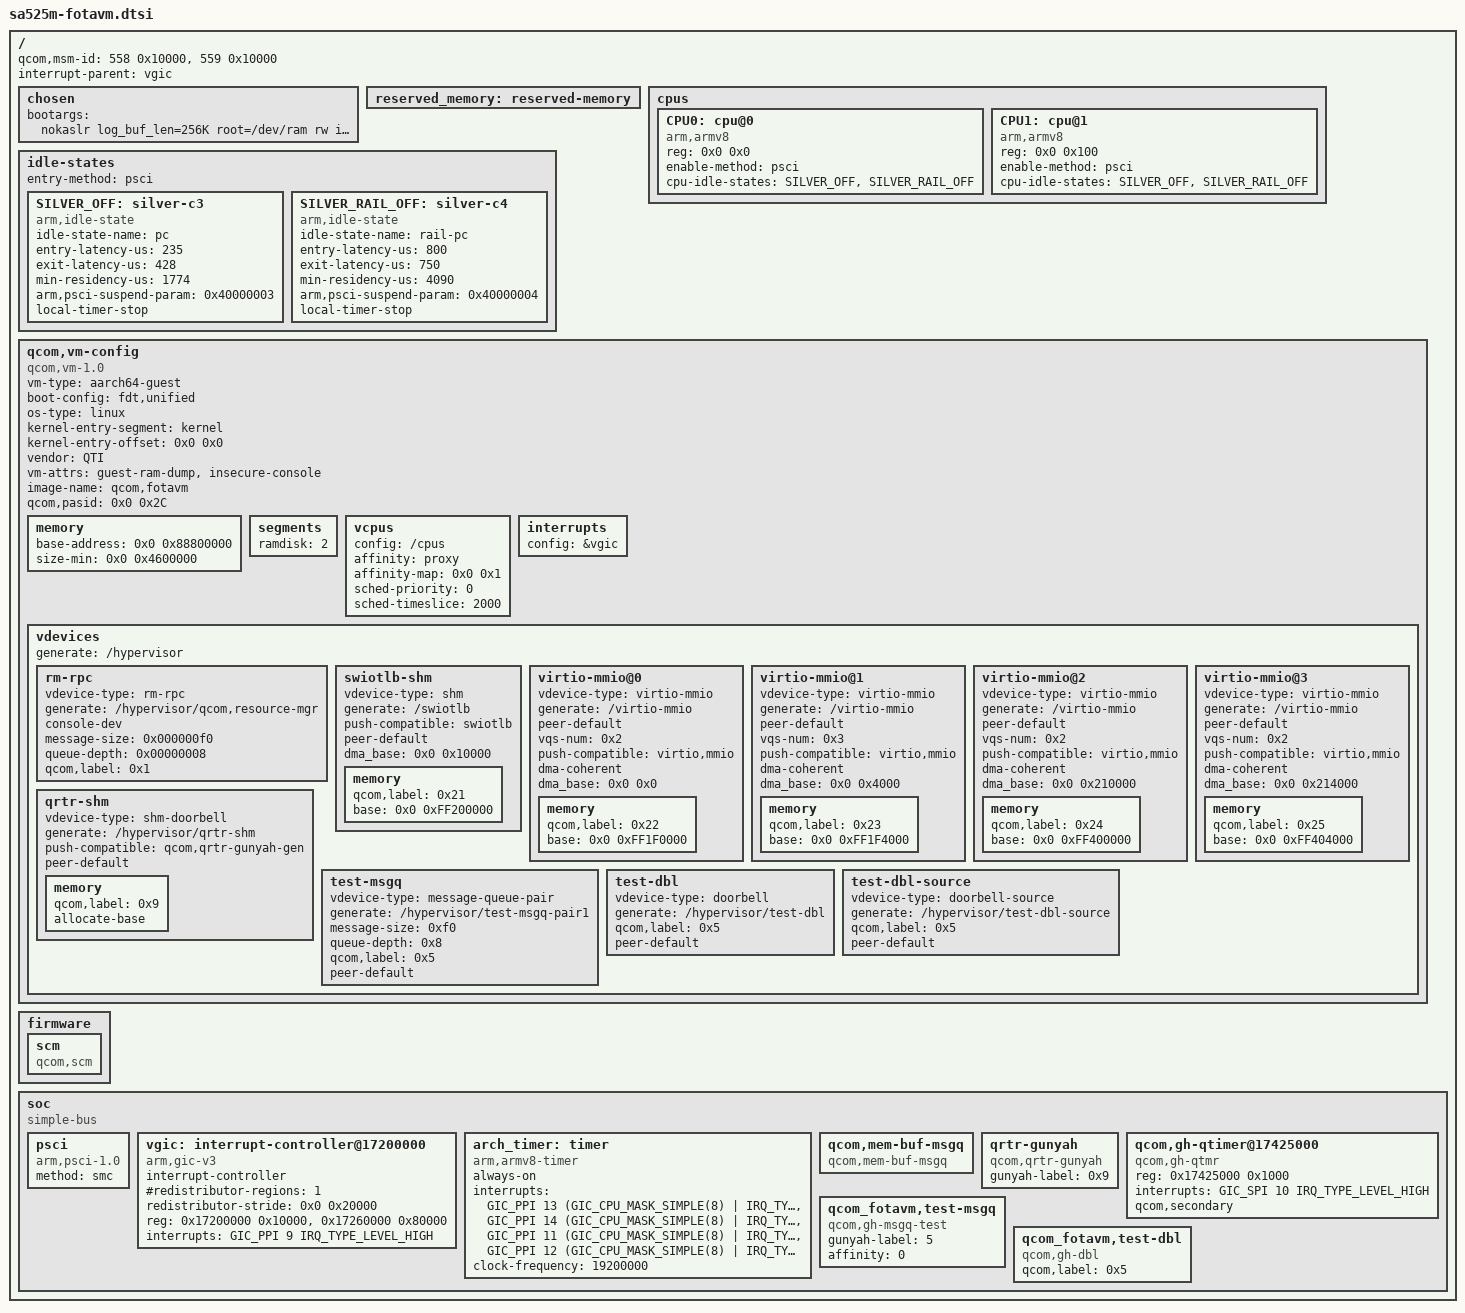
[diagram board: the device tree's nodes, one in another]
#include <dt-bindings/interrupt-controller/arm-gic.h>

/ {
	#address-cells = <0x2>;
	#size-cells = <0x2>;
	qcom,msm-id = <558 0x10000>, <559 0x10000>;
	interrupt-parent = <&vgic>;

	chosen {
		bootargs = "nokaslr log_buf_len=256K root=/dev/ram rw init=/init console=hvc0 loglevel=8";
	};

	reserved_memory: reserved-memory {
		#address-cells = <2>;
		#size-cells = <2>;
		ranges;
	};

	cpus {
		#address-cells = <0x2>;
		#size-cells = <0x0>;

		CPU0: cpu@0 {
			compatible = "arm,armv8";
			reg = <0x0 0x0>;
			device_type = "cpu";
			enable-method = "psci";
			cpu-idle-states = <&SILVER_OFF &SILVER_RAIL_OFF>;
		};

		CPU1: cpu@1 {
			compatible = "arm,armv8";
			reg = <0x0 0x100>;
			device_type = "cpu";
			enable-method = "psci";
			cpu-idle-states = <&SILVER_OFF &SILVER_RAIL_OFF>;
		};

	};

	idle-states {
		entry-method = "psci";

		SILVER_OFF: silver-c3 { /* C3 */
			compatible = "arm,idle-state";
			idle-state-name = "pc";
			entry-latency-us = <235>;
			exit-latency-us = <428>;
			min-residency-us = <1774>;
			arm,psci-suspend-param = <0x40000003>;
			local-timer-stop;
		};

		SILVER_RAIL_OFF: silver-c4 { /* C4 */
			compatible = "arm,idle-state";
			idle-state-name = "rail-pc";
			entry-latency-us = <800>;
			exit-latency-us = <750>;
			min-residency-us = <4090>;
			arm,psci-suspend-param = <0x40000004>;
			local-timer-stop;
		};
	};

	qcom,vm-config {
		compatible = "qcom,vm-1.0";
		vm-type = "aarch64-guest";
		boot-config = "fdt,unified";
		os-type = "linux";
		kernel-entry-segment = "kernel";
		kernel-entry-offset = <0x0 0x0>;
		vendor = "QTI";
		vm-attrs = "guest-ram-dump", "insecure-console";
		image-name = "qcom,fotavm";
		qcom,pasid = <0x0 0x2C>;

		memory {
			#address-cells = <0x2>;
			#size-cells = <0x0>;
			base-address = <0x0 0x88800000>;
			size-min = <0x0 0x4600000>; /* 70 MB */
		};

		segments {
			ramdisk = <2>; /* 8 MB */
		};

		vcpus {
			config = "/cpus";
			affinity = "proxy";
			affinity-map = <0x0 0x1>;
			sched-priority = <0>;       /* relative to PVM */
			sched-timeslice = <2000>;   /* in ms */
		};

		interrupts {
			config = &vgic;
		};

		vdevices {
			generate = "/hypervisor";
			rm-rpc {
				vdevice-type = "rm-rpc";
				generate = "/hypervisor/qcom,resource-mgr";
				console-dev;
				message-size = <0x000000f0>;
				queue-depth = <0x00000008>;
				qcom,label = <0x1>;
			};

			swiotlb-shm {
				vdevice-type = "shm";
				generate = "/swiotlb";
				push-compatible = "swiotlb";
				peer-default;
				dma_base = <0x0 0x10000>;
				memory {
					qcom,label = <0x21>;
					#address-cells = <0x2>;
					base = <0x0 0xFF200000>; /* 2MB aligned*/

				};
			};

			virtio-mmio@0 {
				vdevice-type = "virtio-mmio";
				generate = "/virtio-mmio";
				peer-default;
				vqs-num = <0x2>;
				push-compatible = "virtio,mmio";
				dma-coherent;
				dma_base = <0x0 0x0>;
				memory {
					qcom,label = <0x22>;	//for sdcard.img
					#address-cells = <0x2>;
					base = <0x0 0xFF1F0000>;
				};
			};

			virtio-mmio@1 {
				vdevice-type = "virtio-mmio";
				generate = "/virtio-mmio";
				peer-default;
				vqs-num = <0x3>;
				push-compatible = "virtio,mmio";
				dma-coherent;
				dma_base = <0x0 0x4000>;
				memory {
					qcom,label = <0x23>;	//for net
					#address-cells = <0x2>;
					base = <0x0 0xFF1F4000>;
				};
			};

			virtio-mmio@2 {
				vdevice-type = "virtio-mmio";
				generate = "/virtio-mmio";
				peer-default;
				vqs-num = <0x2>;
				push-compatible = "virtio,mmio";
				dma-coherent;
				dma_base = <0x0 0x210000>;
				memory {
					qcom,label = <0x24>;	//for systemrw.img
					#address-cells = <0x2>;
					base = <0x0 0xFF400000>;
				};
			};

			virtio-mmio@3 {
				vdevice-type = "virtio-mmio";
				generate = "/virtio-mmio";
				peer-default;
				vqs-num = <0x2>;
				push-compatible = "virtio,mmio";
				dma-coherent;
				dma_base = <0x0 0x214000>;
				memory {
					qcom,label = <0x25>;	//for system.img
					#address-cells = <0x2>;
					base = <0x0 0xFF404000>;
				};
			};

			qrtr-shm {
				vdevice-type = "shm-doorbell";
				generate = "/hypervisor/qrtr-shm";
				push-compatible = "qcom,qrtr-gunyah-gen";
				peer-default;
				memory {
					qcom,label = <0x9>;
					allocate-base;
				};
			};

			test-msgq {
				vdevice-type = "message-queue-pair";
				generate = "/hypervisor/test-msgq-pair1";
				message-size = <0xf0>;
				queue-depth = <0x8>;
				qcom,label = <0x5>;
				peer-default;
			};

			test-dbl {
				vdevice-type = "doorbell";
				generate = "/hypervisor/test-dbl";
				qcom,label = <0x5>;
				peer-default;
			};

			test-dbl-source {
				vdevice-type = "doorbell-source";
				generate = "/hypervisor/test-dbl-source";
				qcom,label = <0x5>;
				peer-default;
			};
		};
	};

	firmware: firmware {
		scm {
			compatible = "qcom,scm";
		};
	};

	soc: soc { };
};

&soc {
	#address-cells = <1>;
	#size-cells = <1>;
	ranges = <0 0 0 0xffffffff>;
	compatible = "simple-bus";

	psci {
		compatible = "arm,psci-1.0";
		method = "smc";
	};

	vgic: interrupt-controller@17200000 {
		compatible = "arm,gic-v3";
		#interrupt-cells = <3>;
		interrupt-controller;
		#redistributor-regions = <1>;
		redistributor-stride = <0x0 0x20000>;
		reg = <0x17200000 0x10000>,/* GICD */
			<0x17260000 0x80000>;/* GICR * 4 */
		interrupts = <GIC_PPI 9 IRQ_TYPE_LEVEL_HIGH>;
	};

	arch_timer: timer {
		compatible = "arm,armv8-timer";
		always-on;
		interrupts = <GIC_PPI 13 (GIC_CPU_MASK_SIMPLE(8) | IRQ_TYPE_LEVEL_LOW)>,
			<GIC_PPI 14 (GIC_CPU_MASK_SIMPLE(8) | IRQ_TYPE_LEVEL_LOW)>,
			<GIC_PPI 11 (GIC_CPU_MASK_SIMPLE(8) | IRQ_TYPE_LEVEL_LOW)>,
			<GIC_PPI 12 (GIC_CPU_MASK_SIMPLE(8) | IRQ_TYPE_LEVEL_LOW)>;
		clock-frequency = <19200000>;

	};

	qcom,mem-buf-msgq {
		compatible = "qcom,mem-buf-msgq";
	};

	qrtr-gunyah {
		compatible = "qcom,qrtr-gunyah";
		gunyah-label = <0x9>;
	};

	qcom,gh-qtimer@17425000 {
		compatible = "qcom,gh-qtmr";
		reg = <0x17425000 0x1000>;
		reg-names = "qtmr-base";
		interrupts = <GIC_SPI 10 IRQ_TYPE_LEVEL_HIGH>;
		interrupt-names = "qcom,qtmr-intr";
		qcom,secondary;
	};

	qcom_fotavm,test-msgq {
		compatible = "qcom,gh-msgq-test";
		gunyah-label = <5>;
		affinity = <0>;
	};

	qcom_fotavm,test-dbl {
		compatible = "qcom,gh-dbl";
		qcom,label = <0x5>;
	};
};
